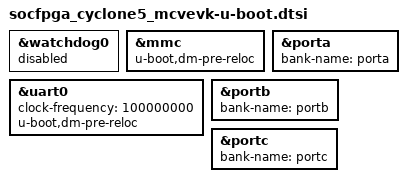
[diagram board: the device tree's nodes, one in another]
// SPDX-License-Identifier: GPL-2.0+
/*
 * U-Boot additions
 *
 * Copyright (C) 2015 Marek Vasut <marex@denx.de>
 * Copyright (C) 2019 Wolfgang Grandegger <wg@aries-embedded.de>
 */

#include "socfpga-common-u-boot.dtsi"

&watchdog0 {
	status = "disabled";
};

&mmc {
	u-boot,dm-pre-reloc;
};

&uart0 {
	clock-frequency = <100000000>;
	u-boot,dm-pre-reloc;
};

&porta {
	bank-name = "porta";
};

&portb {
	bank-name = "portb";
};

&portc {
	bank-name = "portc";
};
